# STM32G474xx register map
File version: 1.5
CPU: CM4 r0p1, little endian, MPU, FPU, 4 interrupt priority bits
Registers are 32-bit, read-write, reset 0x0 unless marked. A register's access mark holds for its fields unless they carry their own. Offsets are from the block's base; [hi:lo] are bit positions.

## QUADSPI — QuadSPI interface
Base 0xA0001000
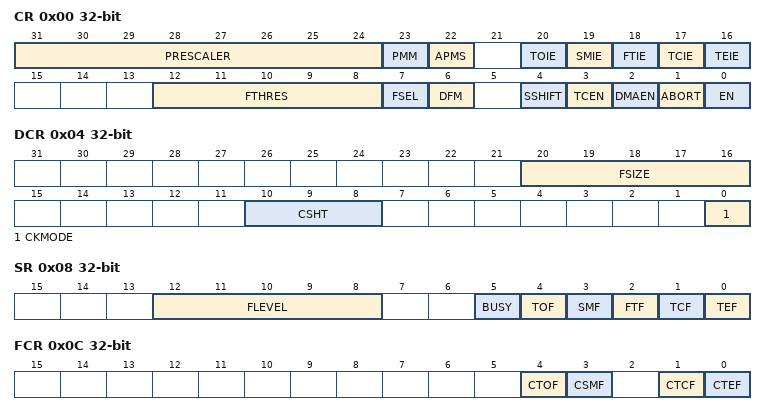
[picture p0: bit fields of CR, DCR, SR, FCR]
0x00 CR — control register
  [31:24] PRESCALER — Clock prescaler
  [23] PMM — Polling match mode
  [22] APMS — Automatic poll mode stop
  [20] TOIE — TimeOut interrupt enable
  [19] SMIE — Status match interrupt enable
  [18] FTIE — FIFO threshold interrupt enable
  [17] TCIE — Transfer complete interrupt enable
  [16] TEIE — Transfer error interrupt enable
  [12:8] FTHRES — IFO threshold level
  [7] FSEL
  [6] DFM
  [4] SSHIFT — Sample shift
  [3] TCEN — Timeout counter enable
  [2] DMAEN — DMA enable
  [1] ABORT — Abort request
  [0] EN — Enable
0x04 DCR — device configuration register
  [20:16] FSIZE — FLASH memory size
  [10:8] CSHT — Chip select high time
  [0] CKMODE — Mode 0 / mode 3
0x08 SR ro — status register
  [12:8] FLEVEL — FIFO level
  [5] BUSY
  [4] TOF — Timeout flag
  [3] SMF — Status match flag
  [2] FTF — FIFO threshold flag
  [1] TCF — Transfer complete flag
  [0] TEF — Transfer error flag
0x0C FCR — flag clear register
  [4] CTOF — Clear timeout flag
  [3] CSMF — Clear status match flag
  [1] CTCF — Clear transfer complete flag
  [0] CTEF — Clear transfer error flag
0x10 DLR — data length register
  [31:0] DL — Data length
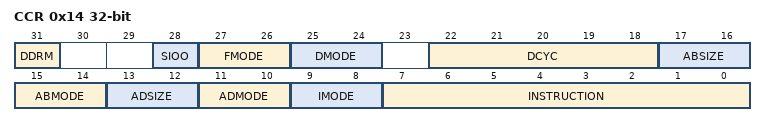
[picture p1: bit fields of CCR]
0x14 CCR — communication configuration register
  [31] DDRM — Double data rate mode
  [28] SIOO — Send instruction only once mode
  [27:26] FMODE — Functional mode
  [25:24] DMODE — Data mode
  [22:18] DCYC — Number of dummy cycles
  [17:16] ABSIZE — Alternate bytes size
  [15:14] ABMODE — Alternate bytes mode
  [13:12] ADSIZE — Address size
  [11:10] ADMODE — Address mode
  [9:8] IMODE — Instruction mode
  [7:0] INSTRUCTION
0x18 AR — address register
  [31:0] ADDRESS
0x1C ABR
  [31:0] ALTERNATE
0x20 DR — data register
  [31:0] DATA
0x24 PSMKR — polling status mask register
  [31:0] MASK — Status mask
0x28 PSMAR — polling status match register
  [31:0] MATCH — Status match
0x2C PIR — polling interval register
  [15:0] INTERVAL — Polling interval
0x30 LPTR — low-power timeout register
  [15:0] TIMEOUT — Timeout period

## ADC12_Common — Analog-to-Digital Converter
Base 0x50000300
Same registers: ADC345_Common 0x50000700
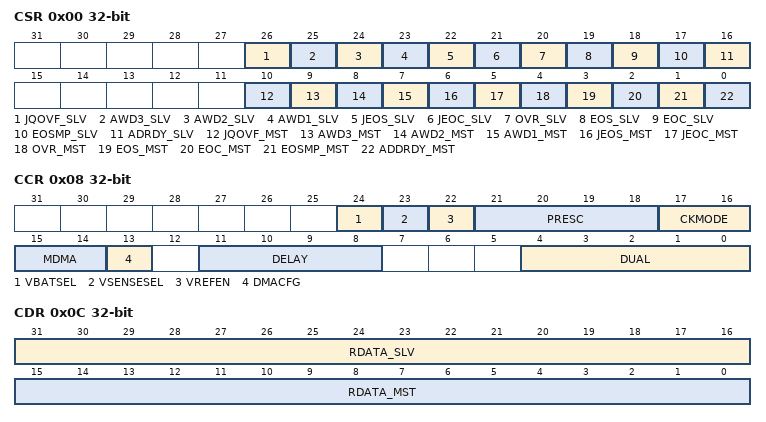
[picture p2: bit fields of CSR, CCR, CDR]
0x00 CSR ro — ADC Common status register
  [26] JQOVF_SLV — Injected Context Queue Overflow flag of the slave ADC
  [25] AWD3_SLV — Analog watchdog 3 flag of the slave ADC
  [24] AWD2_SLV — Analog watchdog 2 flag of the slave ADC
  [23] AWD1_SLV — Analog watchdog 1 flag of the slave ADC
  [22] JEOS_SLV — End of injected sequence flag of the slave ADC
  [21] JEOC_SLV — End of injected conversion flag of the slave ADC
  [20] OVR_SLV — Overrun flag of the slave ADC
  [19] EOS_SLV — End of regular sequence flag of the slave ADC
  [18] EOC_SLV — End of regular conversion of the slave ADC
  [17] EOSMP_SLV
  [16] ADRDY_SLV
  [10] JQOVF_MST
  [9] AWD3_MST
  [8] AWD2_MST
  [7] AWD1_MST
  [6] JEOS_MST
  [5] JEOC_MST
  [4] OVR_MST
  [3] EOS_MST
  [2] EOC_MST
  [1] EOSMP_MST
  [0] ADDRDY_MST
0x08 CCR — ADC common control register
  [24] VBATSEL — VBAT selection
  [23] VSENSESEL — VTS selection
  [22] VREFEN — VREFINT enable
  [21:18] PRESC — ADC prescaler
  [17:16] CKMODE — ADC clock mode
  [15:14] MDMA — Direct memory access mode for multi ADC mode
  [13] DMACFG — DMA configuration (for multi-ADC mode)
  [11:8] DELAY — Delay between 2 sampling phases
  [4:0] DUAL — Dual ADC mode selection
0x0C CDR ro — ADC common regular data register for dual and triple modes
  [31:16] RDATA_SLV — Regular data of the slave ADC
  [15:0] RDATA_MST — Regular data of the master ADC

## FMAC — Filter Math Accelerator
Base 0x40021400
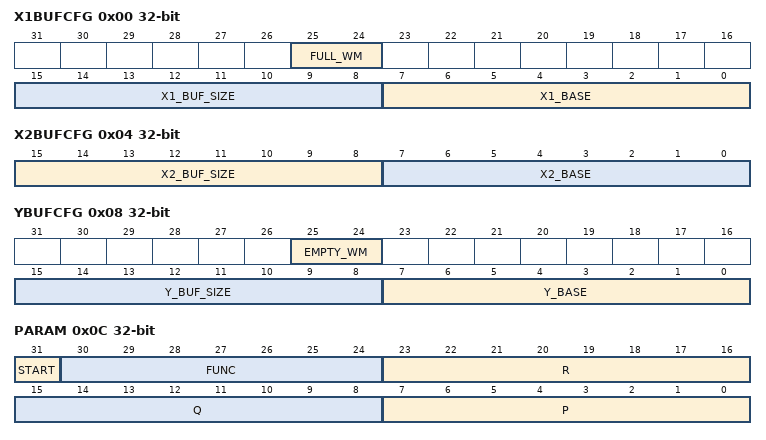
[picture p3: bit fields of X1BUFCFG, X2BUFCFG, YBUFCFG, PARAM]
0x00 X1BUFCFG — FMAC X1 Buffer Configuration register
  [25:24] FULL_WM, [15:8] X1_BUF_SIZE, [7:0] X1_BASE
0x04 X2BUFCFG — FMAC X2 Buffer Configuration register
  [15:8] X2_BUF_SIZE — X1_BUF_SIZE
  [7:0] X2_BASE — X1_BASE
0x08 YBUFCFG — FMAC Y Buffer Configuration register
  [25:24] EMPTY_WM
  [15:8] Y_BUF_SIZE — X1_BUF_SIZE
  [7:0] Y_BASE — X1_BASE
0x0C PARAM — FMAC Parameter register
  [31] START, [30:24] FUNC, [23:16] R, [15:8] Q, [7:0] P
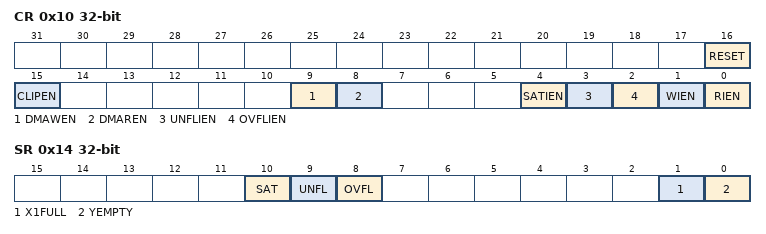
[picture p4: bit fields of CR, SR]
0x10 CR — FMAC Control register
  [16] RESET, [15] CLIPEN, [9] DMAWEN, [8] DMAREN, [4] SATIEN, [3] UNFLIEN, [2] OVFLIEN, [1] WIEN, [0] RIEN
0x14 SR ro — FMAC Status register
  [10] SAT, [9] UNFL, [8] OVFL, [1] X1FULL, [0] YEMPTY
0x18 WDATA wo — FMAC Write Data register
  [15:0] WDATA
0x1C RDATA ro — FMAC Read Data register
  [15:0] RDATA
